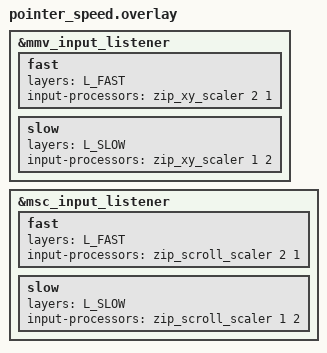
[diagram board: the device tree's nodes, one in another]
/* pointer_speed.overlay */
#include <input/processors.dtsi>

/* Map these to your actual layer numbers if you're not using macros.
 * If you ARE using names in your keymap, define them here:
 */
#define L_FAST  21   /* <-- set to your real L_FAST index */
#define L_SLOW  22   /* <-- set to your real L_SLOW index */

/* Movement (keyboard mouse-keys: &mmv) */
&mmv_input_listener {
    fast {
        layers = <L_FAST>;
        /* 2x speed while L_FAST is held */
        input-processors = <&zip_xy_scaler 2 1>;
    };
    slow {
        layers = <L_SLOW>;
        /* 1/2 speed while L_SLOW is held */
        input-processors = <&zip_xy_scaler 1 2>;
    };
};

/* Optional: scroll speed too (keyboard scroll: &msc) */
&msc_input_listener {
    fast {
        layers = <L_FAST>;
        input-processors = <&zip_scroll_scaler 2 1>;
    };
    slow {
        layers = <L_SLOW>;
        input-processors = <&zip_scroll_scaler 1 2>;
    };
}
